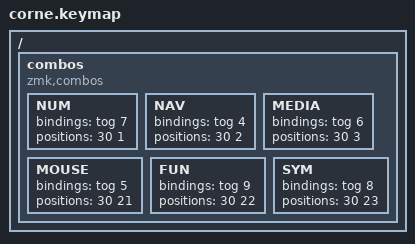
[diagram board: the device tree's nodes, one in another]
// Copyright 2021 Manna Harbour
// https://github.com/manna-harbour/miryoku

#include "../miryoku/custom_config.h"
#include "../miryoku/mapping/42/corne.h"
#include "../miryoku/miryoku.dtsi"

/ {
  combos {
    compatible = "zmk,combos";

    NUM {
      bindings = <&tog 7>;
      key - positions = <30 1>;
    };

    NAV {
      bindings = <&tog 4>;
      key - positions = <30 2>;
    };

    MEDIA {
      bindings = <&tog 6>;
      key - positions = <30 3>;
    };

    MOUSE {
      bindings = <&tog 5>;
      key - positions = <30 21>;
    };

    FUN {
      bindings = <&tog 9>;
      key - positions = <30 22>;
    };

    SYM {
      bindings = <&tog 8>;
      key - positions = <30 23>;
    };
  };
};

